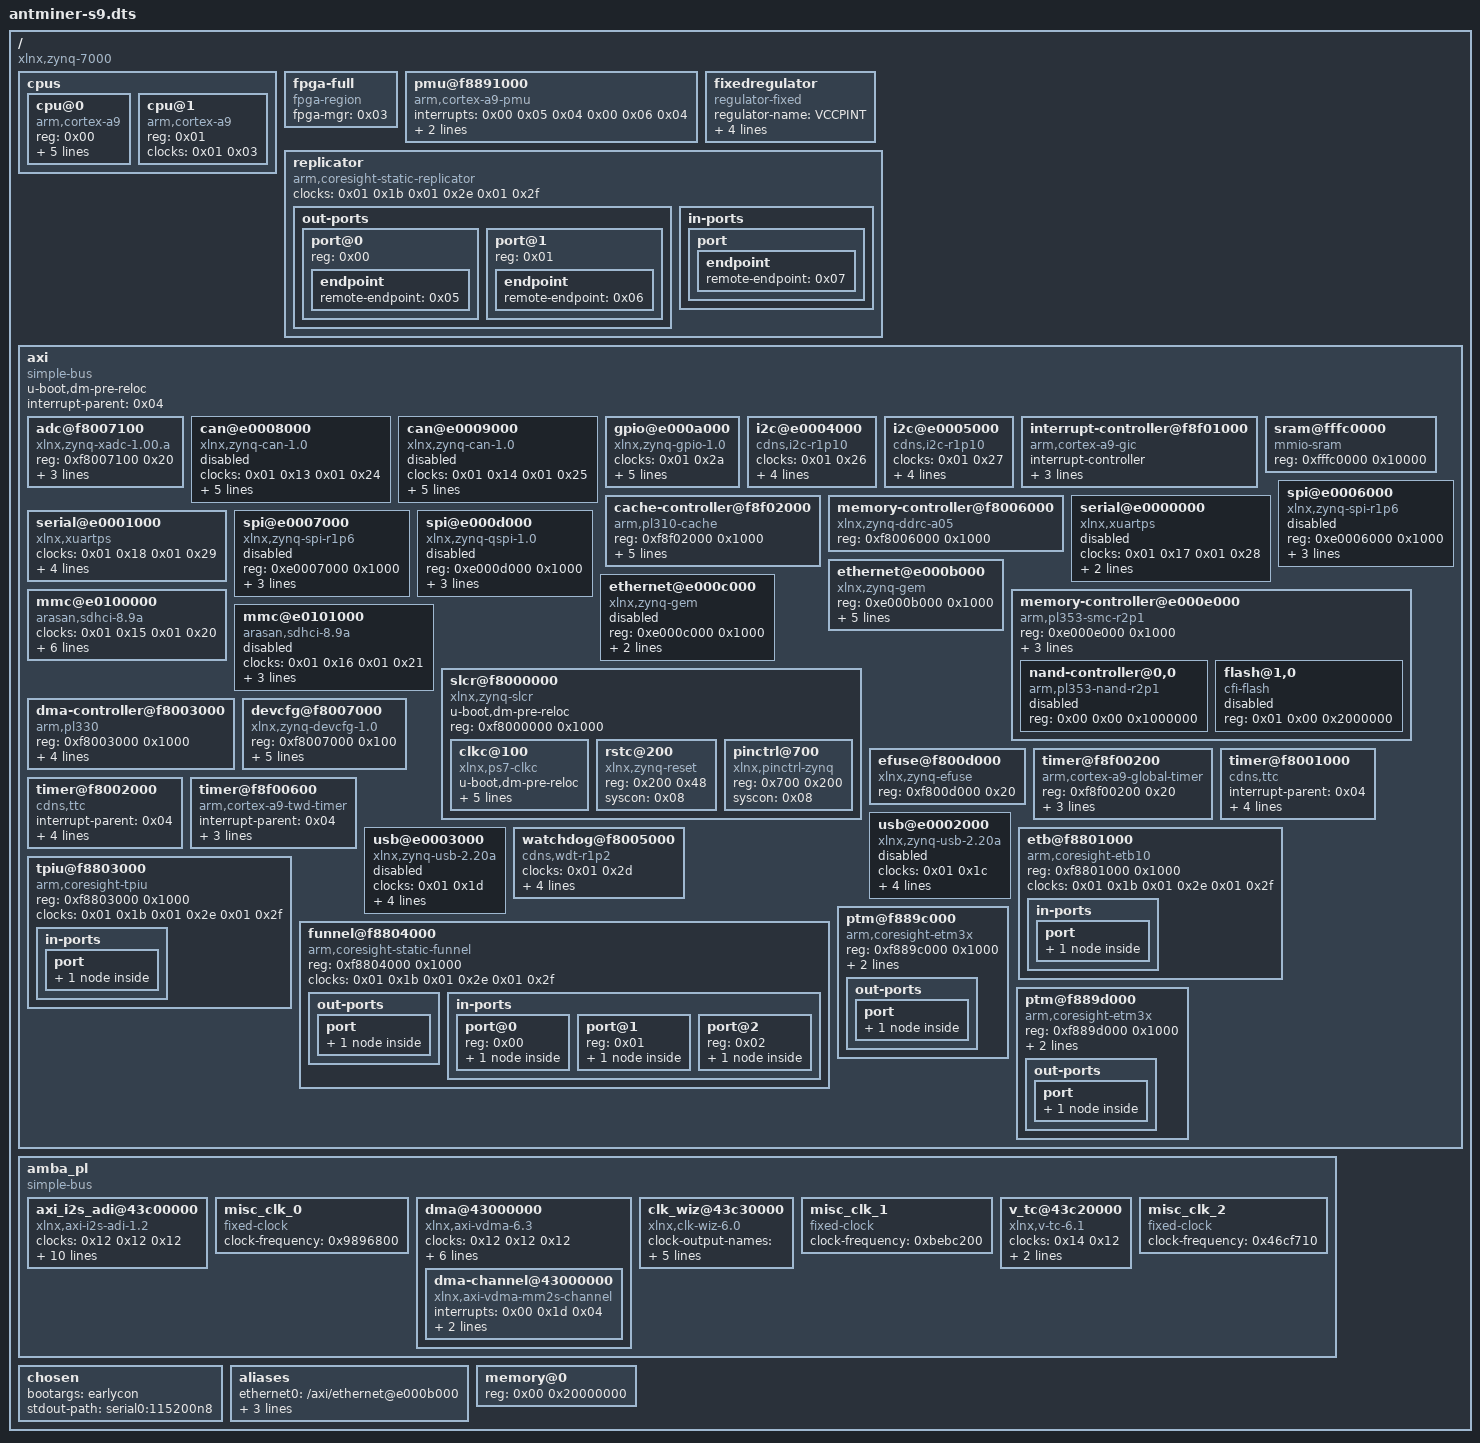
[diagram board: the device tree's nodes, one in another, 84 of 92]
/dts-v1/;

/ {
	#address-cells = <0x01>;
	#size-cells = <0x01>;
	compatible = "xlnx,zynq-7000";

	cpus {
		#address-cells = <0x01>;
		#size-cells = <0x00>;

		cpu@0 {
			compatible = "arm,cortex-a9";
			device_type = "cpu";
			reg = <0x00>;
			clocks = <0x01 0x03>;
			clock-latency = <0x3e8>;
			cpu0-supply = <0x02>;
			operating-points = <0xa2c2a 0xf4240 0x51615 0xf4240>;
			phandle = <0x0e>;
		};

		cpu@1 {
			compatible = "arm,cortex-a9";
			device_type = "cpu";
			reg = <0x01>;
			clocks = <0x01 0x03>;
			phandle = <0x10>;
		};
	};

	fpga-full {
		compatible = "fpga-region";
		fpga-mgr = <0x03>;
		#address-cells = <0x01>;
		#size-cells = <0x01>;
		ranges;
	};

	pmu@f8891000 {
		compatible = "arm,cortex-a9-pmu";
		interrupts = <0x00 0x05 0x04 0x00 0x06 0x04>;
		interrupt-parent = <0x04>;
		reg = <0xf8891000 0x1000 0xf8893000 0x1000>;
	};

	fixedregulator {
		compatible = "regulator-fixed";
		regulator-name = "VCCPINT";
		regulator-min-microvolt = <0xf4240>;
		regulator-max-microvolt = <0xf4240>;
		regulator-boot-on;
		regulator-always-on;
		phandle = <0x02>;
	};

	replicator {
		compatible = "arm,coresight-static-replicator";
		clocks = <0x01 0x1b 0x01 0x2e 0x01 0x2f>;
		clock-names = "apb_pclk\0dbg_trc\0dbg_apb";

		out-ports {
			#address-cells = <0x01>;
			#size-cells = <0x00>;

			port@0 {
				reg = <0x00>;

				endpoint {
					remote-endpoint = <0x05>;
					phandle = <0x0a>;
				};
			};

			port@1 {
				reg = <0x01>;

				endpoint {
					remote-endpoint = <0x06>;
					phandle = <0x09>;
				};
			};
		};

		in-ports {

			port {

				endpoint {
					remote-endpoint = <0x07>;
					phandle = <0x0b>;
				};
			};
		};
	};

	axi {
		u-boot,dm-pre-reloc;
		compatible = "simple-bus";
		#address-cells = <0x01>;
		#size-cells = <0x01>;
		interrupt-parent = <0x04>;
		ranges;

		adc@f8007100 {
			compatible = "xlnx,zynq-xadc-1.00.a";
			reg = <0xf8007100 0x20>;
			interrupts = <0x00 0x07 0x04>;
			interrupt-parent = <0x04>;
			clocks = <0x01 0x0c>;
		};

		can@e0008000 {
			compatible = "xlnx,zynq-can-1.0";
			status = "disabled";
			clocks = <0x01 0x13 0x01 0x24>;
			clock-names = "can_clk\0pclk";
			reg = <0xe0008000 0x1000>;
			interrupts = <0x00 0x1c 0x04>;
			interrupt-parent = <0x04>;
			tx-fifo-depth = <0x40>;
			rx-fifo-depth = <0x40>;
		};

		can@e0009000 {
			compatible = "xlnx,zynq-can-1.0";
			status = "disabled";
			clocks = <0x01 0x14 0x01 0x25>;
			clock-names = "can_clk\0pclk";
			reg = <0xe0009000 0x1000>;
			interrupts = <0x00 0x33 0x04>;
			interrupt-parent = <0x04>;
			tx-fifo-depth = <0x40>;
			rx-fifo-depth = <0x40>;
		};

		gpio@e000a000 {
			compatible = "xlnx,zynq-gpio-1.0";
			#gpio-cells = <0x02>;
			clocks = <0x01 0x2a>;
			gpio-controller;
			interrupt-controller;
			#interrupt-cells = <0x02>;
			interrupt-parent = <0x04>;
			interrupts = <0x00 0x14 0x04>;
			reg = <0xe000a000 0x1000>;
		};

		i2c@e0004000 {
			compatible = "cdns,i2c-r1p10";
			status = "okay";
			clocks = <0x01 0x26>;
			clock-frequency = <0x61a80>;
			interrupt-parent = <0x04>;
			interrupts = <0x00 0x19 0x04>;
			reg = <0xe0004000 0x1000>;
			#address-cells = <0x01>;
			#size-cells = <0x00>;
		};

		i2c@e0005000 {
			compatible = "cdns,i2c-r1p10";
			status = "okay";
			clocks = <0x01 0x27>;
			clock-frequency = <0x61a80>;
			interrupt-parent = <0x04>;
			interrupts = <0x00 0x30 0x04>;
			reg = <0xe0005000 0x1000>;
			#address-cells = <0x01>;
			#size-cells = <0x00>;
		};

		interrupt-controller@f8f01000 {
			compatible = "arm,cortex-a9-gic";
			#interrupt-cells = <0x03>;
			interrupt-controller;
			reg = <0xf8f01000 0x1000 0xf8f00100 0x100>;
			num_cpus = <0x02>;
			num_interrupts = <0x60>;
			phandle = <0x04>;
		};

		cache-controller@f8f02000 {
			compatible = "arm,pl310-cache";
			reg = <0xf8f02000 0x1000>;
			interrupts = <0x00 0x02 0x04>;
			arm,data-latency = <0x03 0x02 0x02>;
			arm,tag-latency = <0x02 0x02 0x02>;
			cache-unified;
			cache-level = <0x02>;
		};

		memory-controller@f8006000 {
			compatible = "xlnx,zynq-ddrc-a05";
			reg = <0xf8006000 0x1000>;
		};

		sram@fffc0000 {
			compatible = "mmio-sram";
			reg = <0xfffc0000 0x10000>;
		};

		serial@e0000000 {
			compatible = "xlnx,xuartps\0cdns,uart-r1p8";
			status = "disabled";
			clocks = <0x01 0x17 0x01 0x28>;
			clock-names = "uart_clk\0pclk";
			reg = <0xe0000000 0x1000>;
			interrupts = <0x00 0x1b 0x04>;
		};

		serial@e0001000 {
			compatible = "xlnx,xuartps\0cdns,uart-r1p8";
			status = "okay";
			clocks = <0x01 0x18 0x01 0x29>;
			clock-names = "uart_clk\0pclk";
			reg = <0xe0001000 0x1000>;
			interrupts = <0x00 0x32 0x04>;
			cts-override;
			device_type = "serial";
			port-number = <0x00>;
		};

		spi@e0006000 {
			compatible = "xlnx,zynq-spi-r1p6";
			reg = <0xe0006000 0x1000>;
			status = "disabled";
			interrupt-parent = <0x04>;
			interrupts = <0x00 0x1a 0x04>;
			clocks = <0x01 0x19 0x01 0x22>;
			clock-names = "ref_clk\0pclk";
			#address-cells = <0x01>;
			#size-cells = <0x00>;
		};

		spi@e0007000 {
			compatible = "xlnx,zynq-spi-r1p6";
			reg = <0xe0007000 0x1000>;
			status = "disabled";
			interrupt-parent = <0x04>;
			interrupts = <0x00 0x31 0x04>;
			clocks = <0x01 0x1a 0x01 0x23>;
			clock-names = "ref_clk\0pclk";
			#address-cells = <0x01>;
			#size-cells = <0x00>;
		};

		spi@e000d000 {
			compatible = "xlnx,zynq-qspi-1.0";
			reg = <0xe000d000 0x1000>;
			interrupt-parent = <0x04>;
			interrupts = <0x00 0x13 0x04>;
			clocks = <0x01 0x0a 0x01 0x2b>;
			clock-names = "ref_clk\0pclk";
			status = "disabled";
			#address-cells = <0x01>;
			#size-cells = <0x00>;
		};

		ethernet@e000b000 {
			compatible = "xlnx,zynq-gem\0cdns,gem";
			reg = <0xe000b000 0x1000>;
			status = "okay";
			interrupts = <0x00 0x16 0x04>;
			clocks = <0x02 0x0d 0x02 0x1e>;
			clock-names = "pclk\0hclk\0tx_clk";
			#address-cells = <0x01>;
			#size-cells = <0x00>;
			phy-mode = "rgmii-id";
			local-mac-address = [f6 aa 35 00 00 01];
			xlnx,ptp-enet-clock = <0x69f6bcb>;
		};

		ethernet@e000c000 {
			compatible = "xlnx,zynq-gem\0cdns,gem";
			reg = <0xe000c000 0x1000>;
			status = "disabled";
			interrupts = <0x00 0x2d 0x04>;
			clocks = <0x01 0x1f 0x01 0x1f 0x01 0x0e>;
			clock-names = "pclk\0hclk\0tx_clk";
			#address-cells = <0x01>;
			#size-cells = <0x00>;
		};

		memory-controller@e000e000 {
			compatible = "arm,pl353-smc-r2p1\0arm,primecell";
			reg = <0xe000e000 0x1000>;
			status = "okay";
			clock-names = "memclk\0apb_pclk";
			clocks = <0x01 0x0b 0x01 0x2c>;
			ranges = <0x00 0x00 0xe1000000 0x1000000 0x01 0x00 0xe2000000 0x2000000 0x02 0x00 0xe4000000 0x2000000>;
			#address-cells = <0x02>;
			#size-cells = <0x01>;
			interrupt-parent = <0x04>;
			interrupts = <0x00 0x12 0x04>;

			nand-controller@0,0 {
				compatible = "arm,pl353-nand-r2p1";
				reg = <0x00 0x00 0x1000000>;
				status = "disabled";
				#address-cells = <0x01>;
				#size-cells = <0x00>;
			};

			flash@1,0 {
				status = "disabled";
				compatible = "cfi-flash";
				reg = <0x01 0x00 0x2000000>;
				#address-cells = <0x01>;
				#size-cells = <0x01>;
			};
		};

		mmc@e0100000 {
			compatible = "arasan,sdhci-8.9a";
			status = "okay";
			clock-names = "clk_xin\0clk_ahb";
			clocks = <0x01 0x15 0x01 0x20>;
			interrupt-parent = <0x04>;
			interrupts = <0x00 0x18 0x04>;
			reg = <0xe0100000 0x1000>;
			xlnx,has-cd = <0x01>;
			xlnx,has-power = <0x00>;
			xlnx,has-wp = <0x01>;
		};

		mmc@e0101000 {
			compatible = "arasan,sdhci-8.9a";
			status = "disabled";
			clock-names = "clk_xin\0clk_ahb";
			clocks = <0x01 0x16 0x01 0x21>;
			interrupt-parent = <0x04>;
			interrupts = <0x00 0x2f 0x04>;
			reg = <0xe0101000 0x1000>;
		};

		slcr@f8000000 {
			u-boot,dm-pre-reloc;
			#address-cells = <0x01>;
			#size-cells = <0x01>;
			compatible = "xlnx,zynq-slcr\0syscon\0simple-mfd";
			reg = <0xf8000000 0x1000>;
			ranges;
			phandle = <0x08>;

			clkc@100 {
				u-boot,dm-pre-reloc;
				#clock-cells = <0x01>;
				compatible = "xlnx,ps7-clkc";
				fclk-enable = <0x01>;
				clock-output-names = "armpll\0ddrpll\0iopll\0cpu_6or4x\0cpu_3or2x\0cpu_2x\0cpu_1x\0ddr2x\0ddr3x\0dci\0lqspi\0smc\0pcap\0gem0\0gem1\0fclk0\0fclk1\0fclk2\0fclk3\0can0\0can1\0sdio0\0sdio1\0uart0\0uart1\0spi0\0spi1\0dma\0usb0_aper\0usb1_aper\0gem0_aper\0gem1_aper\0sdio0_aper\0sdio1_aper\0spi0_aper\0spi1_aper\0can0_aper\0can1_aper\0i2c0_aper\0i2c1_aper\0uart0_aper\0uart1_aper\0gpio_aper\0lqspi_aper\0smc_aper\0swdt\0dbg_trc\0dbg_apb";
				reg = <0x100 0x100>;
				ps-clk-frequency = <0x1fca051>;
				phandle = <0x01>;
			};

			rstc@200 {
				compatible = "xlnx,zynq-reset";
				reg = <0x200 0x48>;
				#reset-cells = <0x01>;
				syscon = <0x08>;
			};

			pinctrl@700 {
				compatible = "xlnx,pinctrl-zynq";
				reg = <0x700 0x200>;
				syscon = <0x08>;
			};
		};

		dma-controller@f8003000 {
			compatible = "arm,pl330\0arm,primecell";
			reg = <0xf8003000 0x1000>;
			interrupt-parent = <0x04>;
			interrupts = <0x00 0x0d 0x04 0x00 0x0e 0x04 0x00 0x0f 0x04 0x00 0x10 0x04 0x00 0x11 0x04 0x00 0x28 0x04 0x00 0x29 0x04 0x00 0x2a 0x04 0x00 0x2b 0x04>;
			#dma-cells = <0x01>;
			clocks = <0x01 0x1b>;
			clock-names = "apb_pclk";
		};

		devcfg@f8007000 {
			compatible = "xlnx,zynq-devcfg-1.0";
			reg = <0xf8007000 0x100>;
			interrupt-parent = <0x04>;
			interrupts = <0x00 0x08 0x04>;
			clocks = <0x01 0x0c 0x01 0x0f 0x01 0x10 0x01 0x11 0x01 0x12>;
			clock-names = "ref_clk\0fclk0\0fclk1\0fclk2\0fclk3";
			syscon = <0x08>;
			phandle = <0x03>;
		};

		efuse@f800d000 {
			compatible = "xlnx,zynq-efuse";
			reg = <0xf800d000 0x20>;
		};

		timer@f8f00200 {
			compatible = "arm,cortex-a9-global-timer";
			reg = <0xf8f00200 0x20>;
			interrupts = <0x01 0x0b 0x301>;
			interrupt-parent = <0x04>;
			clocks = <0x01 0x04>;
		};

		timer@f8001000 {
			interrupt-parent = <0x04>;
			interrupts = <0x00 0x0a 0x04 0x00 0x0b 0x04 0x00 0x0c 0x04>;
			compatible = "cdns,ttc";
			clocks = <0x01 0x06>;
			reg = <0xf8001000 0x1000>;
		};

		timer@f8002000 {
			interrupt-parent = <0x04>;
			interrupts = <0x00 0x25 0x04 0x00 0x26 0x04 0x00 0x27 0x04>;
			compatible = "cdns,ttc";
			clocks = <0x01 0x06>;
			reg = <0xf8002000 0x1000>;
		};

		timer@f8f00600 {
			interrupt-parent = <0x04>;
			interrupts = <0x01 0x0d 0x301>;
			compatible = "arm,cortex-a9-twd-timer";
			reg = <0xf8f00600 0x20>;
			clocks = <0x01 0x04>;
		};

		usb@e0002000 {
			compatible = "xlnx,zynq-usb-2.20a\0chipidea,usb2";
			status = "disabled";
			clocks = <0x01 0x1c>;
			interrupt-parent = <0x04>;
			interrupts = <0x00 0x15 0x04>;
			reg = <0xe0002000 0x1000>;
			phy_type = "ulpi";
		};

		usb@e0003000 {
			compatible = "xlnx,zynq-usb-2.20a\0chipidea,usb2";
			status = "disabled";
			clocks = <0x01 0x1d>;
			interrupt-parent = <0x04>;
			interrupts = <0x00 0x2c 0x04>;
			reg = <0xe0003000 0x1000>;
			phy_type = "ulpi";
		};

		watchdog@f8005000 {
			clocks = <0x01 0x2d>;
			compatible = "cdns,wdt-r1p2";
			interrupt-parent = <0x04>;
			interrupts = <0x00 0x09 0x01>;
			reg = <0xf8005000 0x1000>;
			timeout-sec = <0x0a>;
		};

		etb@f8801000 {
			compatible = "arm,coresight-etb10\0arm,primecell";
			reg = <0xf8801000 0x1000>;
			clocks = <0x01 0x1b 0x01 0x2e 0x01 0x2f>;
			clock-names = "apb_pclk\0dbg_trc\0dbg_apb";

			in-ports {

				port {

					endpoint {
						remote-endpoint = <0x09>;
						phandle = <0x06>;
					};
				};
			};
		};

		tpiu@f8803000 {
			compatible = "arm,coresight-tpiu\0arm,primecell";
			reg = <0xf8803000 0x1000>;
			clocks = <0x01 0x1b 0x01 0x2e 0x01 0x2f>;
			clock-names = "apb_pclk\0dbg_trc\0dbg_apb";

			in-ports {

				port {

					endpoint {
						remote-endpoint = <0x0a>;
						phandle = <0x05>;
					};
				};
			};
		};

		funnel@f8804000 {
			compatible = "arm,coresight-static-funnel\0arm,primecell";
			reg = <0xf8804000 0x1000>;
			clocks = <0x01 0x1b 0x01 0x2e 0x01 0x2f>;
			clock-names = "apb_pclk\0dbg_trc\0dbg_apb";

			out-ports {

				port {

					endpoint {
						remote-endpoint = <0x0b>;
						phandle = <0x07>;
					};
				};
			};

			in-ports {
				#address-cells = <0x01>;
				#size-cells = <0x00>;

				port@0 {
					reg = <0x00>;

					endpoint {
						remote-endpoint = <0x0c>;
						phandle = <0x0f>;
					};
				};

				port@1 {
					reg = <0x01>;

					endpoint {
						remote-endpoint = <0x0d>;
						phandle = <0x11>;
					};
				};

				port@2 {
					reg = <0x02>;

					endpoint {
					};
				};
			};
		};

		ptm@f889c000 {
			compatible = "arm,coresight-etm3x\0arm,primecell";
			reg = <0xf889c000 0x1000>;
			clocks = <0x01 0x1b 0x01 0x2e 0x01 0x2f>;
			clock-names = "apb_pclk\0dbg_trc\0dbg_apb";
			cpu = <0x0e>;

			out-ports {

				port {

					endpoint {
						remote-endpoint = <0x0f>;
						phandle = <0x0c>;
					};
				};
			};
		};

		ptm@f889d000 {
			compatible = "arm,coresight-etm3x\0arm,primecell";
			reg = <0xf889d000 0x1000>;
			clocks = <0x01 0x1b 0x01 0x2e 0x01 0x2f>;
			clock-names = "apb_pclk\0dbg_trc\0dbg_apb";
			cpu = <0x10>;

			out-ports {

				port {

					endpoint {
						remote-endpoint = <0x11>;
						phandle = <0x0d>;
					};
				};
			};
		};
	};

	amba_pl {
		#address-cells = <0x01>;
		#size-cells = <0x01>;
		compatible = "simple-bus";
		ranges;

		axi_i2s_adi@43c00000 {
			clock-names = "DMA_REQ_TX_ACLK DMA_REQ_RX_ACLK s00_axi_aclk";
			clocks = <0x12 0x12 0x12>;
			compatible = "xlnx,axi-i2s-adi-1.2";
			reg = <0x43c00000 0x10000>;
			xlnx,bclk-pol = <0x00>;
			xlnx,dma-type = <0x01>;
			xlnx,has-rx = <0x01>;
			xlnx,has-tx = <0x01>;
			xlnx,lrclk-pol = <0x00>;
			xlnx,num-ch = <0x01>;
			xlnx,s00-axi-addr-width = <0x06>;
			xlnx,s00-axi-data-width = <0x20>;
			xlnx,slot-width = <0x18>;
		};

		misc_clk_0 {
			#clock-cells = <0x00>;
			clock-frequency = <0x9896800>;
			compatible = "fixed-clock";
			phandle = <0x12>;
		};

		dma@43000000 {
			#dma-cells = <0x01>;
			clock-names = "s_axi_lite_aclk m_axi_mm2s_aclk m_axis_mm2s_aclk";
			clocks = <0x12 0x12 0x12>;
			compatible = "xlnx,axi-vdma-6.3\0xlnx,axi-vdma-1.00.a";
			interrupt-names = "mm2s_introut";
			interrupt-parent = <0x04>;
			interrupts = <0x00 0x1d 0x04>;
			reg = <0x43000000 0x10000>;
			xlnx,addrwidth = <0x20>;
			xlnx,flush-fsync = <0x01>;
			xlnx,num-fstores = <0x01>;

			dma-channel@43000000 {
				compatible = "xlnx,axi-vdma-mm2s-channel";
				interrupts = <0x00 0x1d 0x04>;
				xlnx,datawidth = <0x20>;
				xlnx,device-id = <0x00>;
			};
		};

		clk_wiz@43c30000 {
			#clock-cells = <0x01>;
			clock-names = "s_axi_aclk clk_in1";
			clock-output-names = "0x43c30000-clk_74MHz\0x43c30000-clk_371MHz";
			clocks = <0x12 0x13>;
			compatible = "xlnx,clk-wiz-6.0\0xlnx,clocking-wizard";
			reg = <0x43c30000 0x10000>;
			xlnx,nr-outputs = <0x02>;
			xlnx,speed-grade = <0x01>;
		};

		misc_clk_1 {
			#clock-cells = <0x00>;
			clock-frequency = <0xbebc200>;
			compatible = "fixed-clock";
			phandle = <0x13>;
		};

		v_tc@43c20000 {
			clock-names = "clk s_axi_aclk";
			clocks = <0x14 0x12>;
			compatible = "xlnx,v-tc-6.1\0xlnx,v-tc-6.1";
			reg = <0x43c20000 0x10000>;
			xlnx,generator;
		};

		misc_clk_2 {
			#clock-cells = <0x00>;
			clock-frequency = <0x46cf710>;
			compatible = "fixed-clock";
			phandle = <0x14>;
		};
	};

	chosen {
		bootargs = "earlycon";
		stdout-path = "serial0:115200n8";
	};

	aliases {
		ethernet0 = "/axi/ethernet@e000b000";
		i2c0 = "/axi/i2c@e0004000";
		i2c1 = "/axi/i2c@e0005000";
		serial0 = "/axi/serial@e0001000";
	};

	memory@0 {
		device_type = "memory";
		reg = <0x00 0x20000000>;
	};
};
